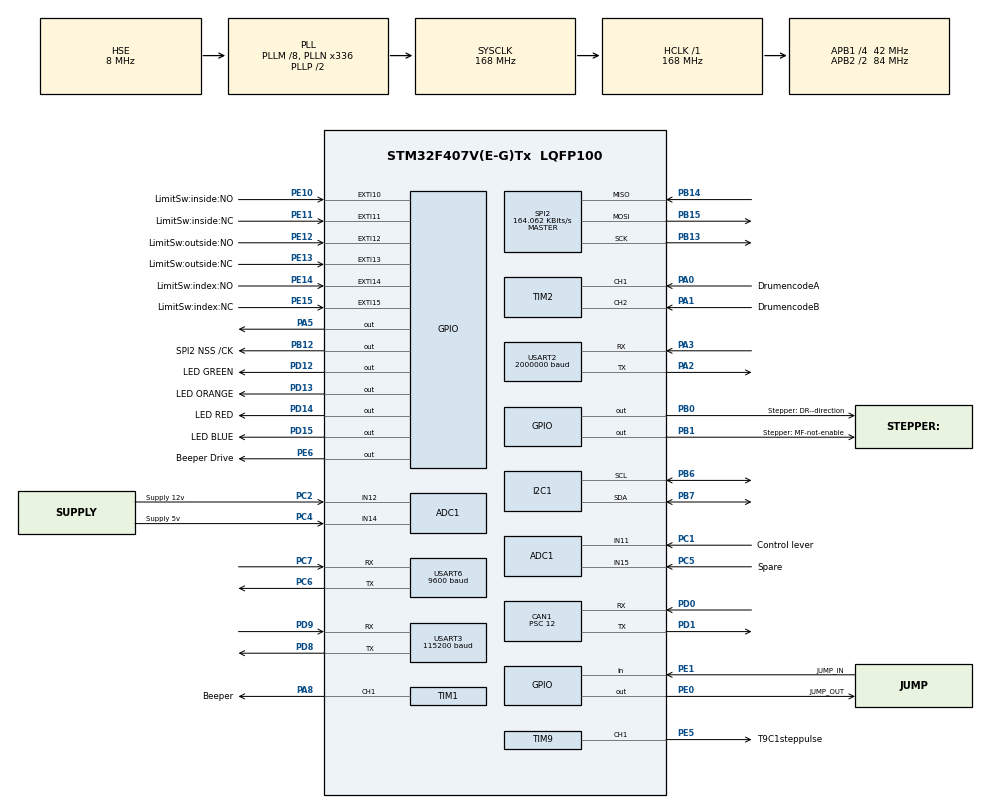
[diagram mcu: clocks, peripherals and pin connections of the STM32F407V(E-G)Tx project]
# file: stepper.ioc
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ADC1.Channel-0\#ChannelRegularConversion=ADC_CHANNEL_11
ADC1.Channel-1\#ChannelRegularConversion=ADC_CHANNEL_12
ADC1.Channel-10\#ChannelRegularConversion=ADC_CHANNEL_TEMPSENSOR
ADC1.Channel-11\#ChannelRegularConversion=ADC_CHANNEL_VREFINT
ADC1.Channel-2\#ChannelRegularConversion=ADC_CHANNEL_14
ADC1.Channel-3\#ChannelRegularConversion=ADC_CHANNEL_15
ADC1.ContinuousConvMode=ENABLE
ADC1.DMAContinuousRequests=ENABLE
ADC1.NbrOfConversion=6
ADC1.NbrOfConversionFlag=1
ADC1.Rank-0\#ChannelRegularConversion=1
ADC1.Rank-1\#ChannelRegularConversion=2
ADC1.Rank-10\#ChannelRegularConversion=5
ADC1.Rank-11\#ChannelRegularConversion=6
ADC1.Rank-2\#ChannelRegularConversion=3
ADC1.Rank-3\#ChannelRegularConversion=4
ADC1.SamplingTime-0\#ChannelRegularConversion=ADC_SAMPLETIME_84CYCLES
ADC1.SamplingTime-1\#ChannelRegularConversion=ADC_SAMPLETIME_84CYCLES
ADC1.SamplingTime-10\#ChannelRegularConversion=ADC_SAMPLETIME_480CYCLES
ADC1.SamplingTime-11\#ChannelRegularConversion=ADC_SAMPLETIME_480CYCLES
ADC1.SamplingTime-2\#ChannelRegularConversion=ADC_SAMPLETIME_84CYCLES
ADC1.SamplingTime-3\#ChannelRegularConversion=ADC_SAMPLETIME_84CYCLES
ADC1.ScanConvMode=ENABLE
ADC1.master=1
CAN1.BS1=CAN_BS1_5TQ
CAN1.CalculateTimeQuantum=285.7142857142857
CAN1.Prescaler=12
Dma.ADC1.4.Direction=DMA_PERIPH_TO_MEMORY
Dma.ADC1.4.FIFOMode=DMA_FIFOMODE_DISABLE
Dma.ADC1.4.Instance=DMA2_Stream0
Dma.ADC1.4.MemDataAlignment=DMA_MDATAALIGN_HALFWORD
Dma.ADC1.4.MemInc=DMA_MINC_ENABLE
Dma.ADC1.4.Mode=DMA_CIRCULAR
Dma.ADC1.4.PeriphDataAlignment=DMA_PDATAALIGN_HALFWORD
Dma.ADC1.4.PeriphInc=DMA_PINC_DISABLE
Dma.ADC1.4.Priority=DMA_PRIORITY_LOW
Dma.I2C1_RX.8.Direction=DMA_PERIPH_TO_MEMORY
Dma.I2C1_RX.8.FIFOMode=DMA_FIFOMODE_DISABLE
Dma.I2C1_RX.8.Instance=DMA1_Stream0
Dma.I2C1_RX.8.MemDataAlignment=DMA_MDATAALIGN_BYTE
Dma.I2C1_RX.8.MemInc=DMA_MINC_ENABLE
Dma.I2C1_RX.8.Mode=DMA_NORMAL
Dma.I2C1_RX.8.PeriphDataAlignment=DMA_PDATAALIGN_BYTE
Dma.I2C1_RX.8.PeriphInc=DMA_PINC_DISABLE
Dma.I2C1_RX.8.Priority=DMA_PRIORITY_LOW
Dma.I2C1_TX.7.Direction=DMA_MEMORY_TO_PERIPH
Dma.I2C1_TX.7.FIFOMode=DMA_FIFOMODE_DISABLE
Dma.I2C1_TX.7.Instance=DMA1_Stream7
Dma.I2C1_TX.7.MemDataAlignment=DMA_MDATAALIGN_BYTE
Dma.I2C1_TX.7.MemInc=DMA_MINC_ENABLE
Dma.I2C1_TX.7.Mode=DMA_NORMAL
Dma.I2C1_TX.7.PeriphDataAlignment=DMA_PDATAALIGN_BYTE
Dma.I2C1_TX.7.PeriphInc=DMA_PINC_DISABLE
Dma.I2C1_TX.7.Priority=DMA_PRIORITY_LOW
Dma.Request0=USART2_RX
Dma.Request1=USART2_TX
Dma.Request2=USART6_RX
Dma.Request3=USART6_TX
Dma.Request4=ADC1
Dma.Request5=USART3_RX
Dma.Request6=USART3_TX
Dma.Request7=I2C1_TX
Dma.Request8=I2C1_RX
Dma.USART2_RX.0.Direction=DMA_PERIPH_TO_MEMORY
Dma.USART2_RX.0.FIFOMode=DMA_FIFOMODE_DISABLE
Dma.USART2_RX.0.Instance=DMA1_Stream5
Dma.USART2_RX.0.MemDataAlignment=DMA_MDATAALIGN_BYTE
Dma.USART2_RX.0.MemInc=DMA_MINC_ENABLE
Dma.USART2_RX.0.Mode=DMA_CIRCULAR
Dma.USART2_RX.0.PeriphDataAlignment=DMA_PDATAALIGN_BYTE
Dma.USART2_RX.0.PeriphInc=DMA_PINC_DISABLE
Dma.USART2_RX.0.Priority=DMA_PRIORITY_LOW
Dma.USART2_TX.1.Direction=DMA_MEMORY_TO_PERIPH
Dma.USART2_TX.1.FIFOMode=DMA_FIFOMODE_DISABLE
Dma.USART2_TX.1.Instance=DMA1_Stream6
Dma.USART2_TX.1.MemDataAlignment=DMA_MDATAALIGN_BYTE
Dma.USART2_TX.1.MemInc=DMA_MINC_ENABLE
Dma.USART2_TX.1.Mode=DMA_NORMAL
Dma.USART2_TX.1.PeriphDataAlignment=DMA_PDATAALIGN_BYTE
Dma.USART2_TX.1.PeriphInc=DMA_PINC_DISABLE
Dma.USART2_TX.1.Priority=DMA_PRIORITY_LOW
Dma.USART3_RX.5.Direction=DMA_PERIPH_TO_MEMORY
Dma.USART3_RX.5.FIFOMode=DMA_FIFOMODE_DISABLE
Dma.USART3_RX.5.Instance=DMA1_Stream1
Dma.USART3_RX.5.MemDataAlignment=DMA_MDATAALIGN_BYTE
Dma.USART3_RX.5.MemInc=DMA_MINC_ENABLE
Dma.USART3_RX.5.Mode=DMA_NORMAL
Dma.USART3_RX.5.PeriphDataAlignment=DMA_PDATAALIGN_BYTE
Dma.USART3_RX.5.PeriphInc=DMA_PINC_DISABLE
Dma.USART3_RX.5.Priority=DMA_PRIORITY_LOW
Dma.USART3_TX.6.Direction=DMA_MEMORY_TO_PERIPH
Dma.USART3_TX.6.FIFOMode=DMA_FIFOMODE_DISABLE
Dma.USART3_TX.6.Instance=DMA1_Stream3
Dma.USART3_TX.6.MemDataAlignment=DMA_MDATAALIGN_BYTE
Dma.USART3_TX.6.MemInc=DMA_MINC_ENABLE
Dma.USART3_TX.6.Mode=DMA_NORMAL
Dma.USART3_TX.6.PeriphDataAlignment=DMA_PDATAALIGN_BYTE
Dma.USART3_TX.6.PeriphInc=DMA_PINC_DISABLE
Dma.USART3_TX.6.Priority=DMA_PRIORITY_LOW
Dma.USART6_RX.2.Direction=DMA_PERIPH_TO_MEMORY
Dma.USART6_RX.2.FIFOMode=DMA_FIFOMODE_DISABLE
Dma.USART6_RX.2.Instance=DMA2_Stream1
Dma.USART6_RX.2.MemDataAlignment=DMA_MDATAALIGN_BYTE
Dma.USART6_RX.2.MemInc=DMA_MINC_ENABLE
Dma.USART6_RX.2.Mode=DMA_CIRCULAR
Dma.USART6_RX.2.PeriphDataAlignment=DMA_PDATAALIGN_BYTE
Dma.USART6_RX.2.PeriphInc=DMA_PINC_DISABLE
Dma.USART6_RX.2.Priority=DMA_PRIORITY_LOW
Dma.USART6_TX.3.Direction=DMA_MEMORY_TO_PERIPH
Dma.USART6_TX.3.FIFOMode=DMA_FIFOMODE_DISABLE
Dma.USART6_TX.3.Instance=DMA2_Stream6
Dma.USART6_TX.3.MemDataAlignment=DMA_MDATAALIGN_BYTE
Dma.USART6_TX.3.MemInc=DMA_MINC_ENABLE
Dma.USART6_TX.3.Mode=DMA_NORMAL
Dma.USART6_TX.3.PeriphDataAlignment=DMA_PDATAALIGN_BYTE
Dma.USART6_TX.3.PeriphInc=DMA_PINC_DISABLE
Dma.USART6_TX.3.Priority=DMA_PRIORITY_LOW
FREERTOS.INCLUDE_uxTaskGetStackHighWaterMark=1
FREERTOS.INCLUDE_vTaskDelayUntil=1
FREERTOS.INCLUDE_vTaskDelete=0
FREERTOS.INCLUDE_xTaskGetCurrentTaskHandle=1
FREERTOS.MEMORY_ALLOCATION=2
FREERTOS.Tasks01=defaultTask,0,384,StartDefaultTask,Default,NULL,Dynamic,NULL,NULL
FREERTOS.Timers01=defaultTaskTimer,CallbackdefaultTaskTimer,osTimerPeriodic,Default,NULL,Dynamic,NULL
FREERTOS.configCHECK_FOR_STACK_OVERFLOW=2
FREERTOS.configMINIMAL_STACK_SIZE=96
FREERTOS.configQUEUE_REGISTRY_SIZE=12
FREERTOS.configTICK_RATE_HZ=512
FREERTOS.configTOTAL_HEAP_SIZE=32768
FREERTOS.configUSE_TIMERS=1
Mcu.Family=STM32F4
Mcu.Name=STM32F407V(E-G)Tx
Mcu.Package=LQFP100
NVIC.ADC_IRQn=true\:6\:0\:true\:false\:true\:true\:true\:true
NVIC.CAN1_RX0_IRQn=true\:7\:0\:true\:false\:true\:true\:true\:true
NVIC.CAN1_RX1_IRQn=true\:7\:0\:true\:false\:true\:true\:true\:true
NVIC.CAN1_TX_IRQn=true\:7\:0\:true\:false\:true\:true\:true\:true
NVIC.DMA1_Stream0_IRQn=true\:8\:0\:true\:false\:true\:true\:false\:true
NVIC.DMA1_Stream1_IRQn=true\:10\:0\:true\:false\:true\:true\:false\:true
NVIC.DMA1_Stream3_IRQn=true\:10\:0\:true\:false\:true\:true\:false\:true
NVIC.DMA1_Stream5_IRQn=true\:6\:0\:true\:false\:true\:true\:false\:true
NVIC.DMA1_Stream6_IRQn=true\:6\:0\:true\:false\:true\:true\:false\:true
NVIC.DMA1_Stream7_IRQn=true\:12\:0\:true\:false\:true\:true\:false\:true
NVIC.DMA2_Stream0_IRQn=true\:6\:0\:true\:false\:true\:true\:false\:true
NVIC.DMA2_Stream1_IRQn=true\:11\:0\:true\:false\:true\:true\:false\:true
NVIC.DMA2_Stream6_IRQn=true\:11\:0\:true\:false\:true\:true\:false\:true
NVIC.EXTI15_10_IRQn=true\:11\:0\:true\:false\:true\:true\:true\:true
NVIC.I2C1_EV_IRQn=true\:10\:0\:true\:false\:true\:true\:true\:true
NVIC.PriorityGroup=NVIC_PRIORITYGROUP_4
NVIC.SPI2_IRQn=true\:13\:0\:true\:false\:true\:true\:true\:true
NVIC.TIM1_BRK_TIM9_IRQn=true\:4\:0\:true\:false\:true\:false\:true\:true
NVIC.TIM3_IRQn=true\:2\:0\:true\:false\:true\:false\:true\:true
NVIC.TIM8_BRK_TIM12_IRQn=true\:0\:0\:false\:false\:true\:false\:false\:true
NVIC.TimeBase=TIM8_BRK_TIM12_IRQn
NVIC.TimeBaseIP=TIM12
NVIC.USART2_IRQn=true\:6\:0\:true\:false\:true\:true\:true\:true
NVIC.USART3_IRQn=true\:8\:0\:true\:false\:true\:true\:true\:true
NVIC.USART6_IRQn=true\:9\:0\:true\:false\:true\:true\:true\:true
PA0-WKUP.GPIO_Label=DrumencodeA
PA0-WKUP.GPIO_PuPd=GPIO_PULLUP
PA0-WKUP.GPIO_Speed=GPIO_SPEED_FREQ_MEDIUM
PA0-WKUP.Signal=S_TIM2_CH1_ETR
PA1.GPIO_Label=DrumencodeB
PA1.GPIO_PuPd=GPIO_PULLUP
PA1.GPIO_Speed=GPIO_SPEED_FREQ_MEDIUM
PA1.Signal=S_TIM2_CH2
PA13.Mode=Serial_Wire
PA13.Signal=SYS_JTMS-SWDIO
PA14.Mode=Serial_Wire
PA14.Signal=SYS_JTCK-SWCLK
PA2.Mode=Asynchronous
PA2.Signal=USART2_TX
PA3.Mode=Asynchronous
PA3.Signal=USART2_RX
PA5.Signal=GPIO_Output
PA8.GPIO_Label=Beeper
PA8.Signal=S_TIM1_CH1
PB0.GPIO_Label=Stepper\: DR--direction
PB0.GPIO_Speed=GPIO_SPEED_FREQ_MEDIUM
PB0.Signal=GPIO_Output
PB1.GPIO_Label=Stepper\: MF-not-enable
PB1.Signal=GPIO_Output
PB12.GPIO_Label=SPI2 NSS /CK
PB12.GPIO_PuPd=GPIO_PULLUP
PB12.GPIO_Speed=GPIO_SPEED_FREQ_MEDIUM
PB12.Signal=GPIO_Output
PB13.Mode=Full_Duplex_Master
PB13.Signal=SPI2_SCK
PB14.Mode=Full_Duplex_Master
PB14.Signal=SPI2_MISO
PB15.Mode=Full_Duplex_Master
PB15.Signal=SPI2_MOSI
PB6.Mode=I2C
PB6.Signal=I2C1_SCL
PB7.Mode=I2C
PB7.Signal=I2C1_SDA
PC1.GPIO_Label=Control lever
PC1.Signal=ADCx_IN11
PC2.GPIO_Label=Supply 12v
PC2.Signal=ADCx_IN12
PC4.GPIO_Label=Supply 5v
PC4.Signal=ADCx_IN14
PC5.GPIO_Label=Spare
PC5.Signal=ADCx_IN15
PC6.Mode=Asynchronous
PC6.Signal=USART6_TX
PC7.Mode=Asynchronous
PC7.Signal=USART6_RX
PD0.Mode=Master
PD0.Signal=CAN1_RX
PD1.Mode=Master
PD1.Signal=CAN1_TX
PD12.GPIO_Label=LED GREEN
PD12.Signal=GPIO_Output
PD13.GPIO_Label=LED ORANGE
PD13.Signal=GPIO_Output
PD14.GPIO_Label=LED RED
PD14.Signal=GPIO_Output
PD15.GPIO_Label=LED BLUE
PD15.Signal=GPIO_Output
PD8.Mode=Asynchronous
PD8.Signal=USART3_TX
PD9.Mode=Asynchronous
PD9.Signal=USART3_RX
PE0.GPIO_Label=JUMP_OUT
PE0.GPIO_Speed=GPIO_SPEED_FREQ_MEDIUM
PE0.Signal=GPIO_Output
PE1.GPIO_Label=JUMP_IN
PE1.GPIO_PuPd=GPIO_PULLDOWN
PE1.Signal=GPIO_Input
PE10.GPIO_Label=LimitSw\:inside\:NO
PE10.GPIO_PuPd=GPIO_PULLUP
PE10.Signal=GPXTI10
PE11.GPIO_Label=LimitSw\:inside\:NC
PE11.GPIO_PuPd=GPIO_PULLUP
PE11.Signal=GPXTI11
PE12.GPIO_Label=LimitSw\:outside\:NO
PE12.GPIO_PuPd=GPIO_PULLUP
PE12.Signal=GPXTI12
PE13.GPIO_Label=LimitSw\:outside\:NC
PE13.GPIO_PuPd=GPIO_PULLUP
PE13.Signal=GPXTI13
PE14.GPIO_Label=LimitSw\:index\:NO
PE14.GPIO_PuPd=GPIO_PULLUP
PE14.Signal=GPXTI14
PE15.GPIO_Label=LimitSw\:index\:NC
PE15.GPIO_PuPd=GPIO_PULLUP
PE15.Signal=GPXTI15
PE5.GPIO_Label=T9C1steppulse
PE5.GPIO_PuPd=GPIO_PULLUP
PE5.GPIO_Speed=GPIO_SPEED_FREQ_VERY_HIGH
PE5.Signal=S_TIM9_CH1
PE6.GPIO_Label=Beeper Drive
PE6.GPIO_ModeDefaultOutputPP=GPIO_MODE_OUTPUT_PP
PE6.GPIO_PuPd=GPIO_NOPULL
PE6.GPIO_Speed=GPIO_SPEED_FREQ_LOW
PE6.PinState=GPIO_PIN_RESET
PE6.Signal=GPIO_Output
PH0-OSC_IN.Mode=HSE-External-Oscillator
PH0-OSC_IN.Signal=RCC_OSC_IN
PH1-OSC_OUT.Mode=HSE-External-Oscillator
PH1-OSC_OUT.Signal=RCC_OSC_OUT
ProjectManager.HeapSize=0x200
ProjectManager.StackSize=0x400
ProjectManager.TargetToolchain=Makefile
RCC.48MHZClocksFreq_Value=48000000
RCC.AHBFreq_Value=168000000
RCC.APB1CLKDivider=RCC_HCLK_DIV4
RCC.APB1Freq_Value=42000000
RCC.APB1TimFreq_Value=84000000
RCC.APB2CLKDivider=RCC_HCLK_DIV2
RCC.APB2Freq_Value=84000000
RCC.APB2TimFreq_Value=168000000
RCC.CortexFreq_Value=168000000
RCC.HCLKFreq_Value=168000000
RCC.HSE_VALUE=8000000
RCC.HSI_VALUE=16000000
RCC.LSE_VALUE=32768
RCC.PLLM=8
RCC.PLLN=336
RCC.PLLQ=7
RCC.PLLSourceVirtual=RCC_PLLSOURCE_HSE
RCC.SYSCLKFreq_VALUE=168000000
RCC.SYSCLKSource=RCC_SYSCLKSOURCE_PLLCLK
RCC.VCOOutputFreq_Value=336000000
SH.ADCx_IN11.0=ADC1_IN11,IN11
SH.ADCx_IN12.0=ADC1_IN12,IN12
SH.ADCx_IN14.0=ADC1_IN14,IN14
SH.ADCx_IN15.0=ADC1_IN15,IN15
SH.S_TIM1_CH1.0=TIM1_CH1,PWM Generation1 CH1
SH.S_TIM2_CH1_ETR.0=TIM2_CH1,Encoder_Interface
SH.S_TIM2_CH2.0=TIM2_CH2,Encoder_Interface
SH.S_TIM9_CH1.0=TIM9_CH1,PWM Generation1 CH1
SPI2.BaudRatePrescaler=SPI_BAUDRATEPRESCALER_256
SPI2.CLKPhase=SPI_PHASE_1EDGE
SPI2.CLKPolarity=SPI_POLARITY_LOW
SPI2.CalculateBaudRate=164.062 KBits/s
SPI2.Direction=SPI_DIRECTION_2LINES
SPI2.Mode=SPI_MODE_MASTER
SPI2.VirtualType=VM_MASTER
TIM1.AutoReloadPreload=TIM_AUTORELOAD_PRELOAD_DISABLE
TIM1.Channel-PWM\ Generation1\ CH1=TIM_CHANNEL_1
TIM1.Period=35000
TIM1.Pulse-PWM\ Generation1\ CH1=15700
TIM1.TIM_MasterOutputTrigger=TIM_TRGO_OC1REF
TIM3.Channel-Output\ Compare1\ No\ Output=TIM_CHANNEL_1
TIM3.Period=1680
TIM5.Channel-Output\ Compare1\ No\ Output=TIM_CHANNEL_1
TIM9.Channel-PWM\ Generation1\ CH1=TIM_CHANNEL_1
TIM9.OCPolarity_1=TIM_OCPOLARITY_HIGH
TIM9.Period=1680
TIM9.Pulse-PWM\ Generation1\ CH1=504
USART2.BaudRate=2000000
USART2.VirtualMode=VM_ASYNC
USART3.BaudRate=115200
USART3.VirtualMode=VM_ASYNC
USART6.BaudRate=9600
USART6.VirtualMode=VM_ASYNC
VP_ADC1_TempSens_Input.Mode=IN-TempSens
VP_ADC1_Vref_Input.Mode=IN-Vrefint
VP_FREERTOS_VS_CMSIS_V1.Mode=CMSIS_V1
VP_SYS_VS_tim12.Mode=TIM12
VP_TIM1_VS_ClockSourceINT.Mode=Internal
VP_TIM3_VS_ClockSourceINT.Mode=Internal
VP_TIM3_VS_no_output1.Mode=Output Compare1 No Output
VP_TIM5_VS_ClockSourceINT.Mode=Internal
VP_TIM5_VS_no_output1.Mode=Output Compare1 No Output
VP_TIM9_VS_ClockSourceINT.Mode=Internal
VP_TIM9_VS_OPM.Mode=OPM_bit
board=custom

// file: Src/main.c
/* USER CODE BEGIN Header */
/**
  ******************************************************************************
  * @file           : main.c
  * @brief          : Main program body
  ******************************************************************************
  * This notice applies to any and all portions of this file
  * that are not between comment pairs USER CODE BEGIN and
  * USER CODE END. Other portions of this file, whether
  * inserted by the user or by software development tools
  * are owned by their respective copyright owners.
  *
  * Copyright (c) 2019 STMicroelectronics International N.V.
  * All rights reserved.
  *
  * Redistribution and use in source and binary forms, with or without
  * modification, are permitted, provided that the following conditions are met:
  *
  * 1. Redistribution of source code must retain the above copyright notice,
  *    this list of conditions and the following disclaimer.
  * 2. Redistributions in binary form must reproduce the above copyright notice,
  *    this list of conditions and the following disclaimer in the documentation
  *    and/or other materials provided with the distribution.
  * 3. Neither the name of STMicroelectronics nor the names of other
  *    contributors to this software may be used to endorse or promote products
  *    derived from this software without specific written permission.
  * 4. This software, including modifications and/or derivative works of this
  *    software, must execute solely and exclusively on microcontroller or
  *    microprocessor devices manufactured by or for STMicroelectronics.
  * 5. Redistribution and use of this software other than as permitted under
  *    this license is void and will automatically terminate your rights under
  *    this license.
  *
  * THIS SOFTWARE IS PROVIDED BY STMICROELECTRONICS AND CONTRIBUTORS "AS IS"
  * AND ANY EXPRESS, IMPLIED OR STATUTORY WARRANTIES, INCLUDING, BUT NOT
  * LIMITED TO, THE IMPLIED WARRANTIES OF MERCHANTABILITY, FITNESS FOR A
  * PARTICULAR PURPOSE AND NON-INFRINGEMENT OF THIRD PARTY INTELLECTUAL PROPERTY
  * RIGHTS ARE DISCLAIMED TO THE FULLEST EXTENT PERMITTED BY LAW. IN NO EVENT
  * SHALL STMICROELECTRONICS OR CONTRIBUTORS BE LIABLE FOR ANY DIRECT, INDIRECT,
  * INCIDENTAL, SPECIAL, EXEMPLARY, OR CONSEQUENTIAL DAMAGES (INCLUDING, BUT NOT
  * LIMITED TO, PROCUREMENT OF SUBSTITUTE GOODS OR SERVICES; LOSS OF USE, DATA,
  * OR PROFITS; OR BUSINESS INTERRUPTION) HOWEVER CAUSED AND ON ANY THEORY OF
  * LIABILITY, WHETHER IN CONTRACT, STRICT LIABILITY, OR TORT (INCLUDING
  * NEGLIGENCE OR OTHERWISE) ARISING IN ANY WAY OUT OF THE USE OF THIS SOFTWARE,
  * EVEN IF ADVISED OF THE POSSIBILITY OF SUCH DAMAGE.
  *
  ******************************************************************************
  */
/* USER CODE END Header */
#include "main.h"
#include "cmsis_os.h"

/* USER CODE BEGIN Includes */
#include <string.h>
#include "SerialTaskSend.h"
#include "stm32f4xx_hal_pcd.h"
//#include "usbd_cdc_if.h"
#include "cdc_txbuff.h"
#include "CanTask.h"
#include "can_iface.h"
#include "canfilter_setup.h"
#include "stm32f4xx_hal_can.h"
#include "getserialbuf.h"
#include "stackwatermark.h"
#include "yprintf.h"
#include "gateway_comm.h"
#include "gateway_CANtoPC.h"
#include "DTW_counter.h"
#include "SerialTaskReceive.h"
#include "yscanf.h"
#include "adctask.h"
#include "ADCTask.h"
#include "adcparams.h"
#include "adcparamsinit.h"
#include "gateway_PCtoCAN.h"
#include "morse.h"
#include "MailboxTask.h"
#include "GatewayTask.h"
#include "iir_f2.h"
#include "spiserialparallelSW.h"
#include "cdc_txbuff.h"
#include "SpiOutTask.h"
#include "BeepTask.h"
#include "lcdprintf.h"
#include "LEDTask.h"
#include "led_chasing.h"
#include "calib_control_lever.h"
#include "lcdmsg.h"
#include "dmoc_control.h"
#include "control_law_v1.h"

#include "LcdTask.h"
#include "lcd_hd44780_i2c.h"
#include "LcdmsgsTask.h"
#include "LcdmsgsetTask.h"
#include "stepper_items.h"

/* USER CODE END Includes */

/* USER CODE BEGIN PTD */

void* verr[8];
uint32_t verrx = 0;
__attribute__( ( always_inline ) ) __STATIC_INLINE uint32_t __get_SP(void)
{
  register uint32_t result;

  __ASM volatile ("MOV %0, SP\n" : "=r" (result) );
  return(result);
}

uint32_t timectr = 0;
struct CAN_CTLBLOCK* pctl0;	// Pointer to CAN1 control block
struct CAN_CTLBLOCK* pctl1;	// Pointer to CAN2 control block

uint32_t debugTX1b;
uint32_t debugTX1b_prev;

uint32_t debugTX1c;
uint32_t debugTX1c_prev;

uint32_t debug03;
uint32_t debug03_prev;

extern osThreadId SerialTaskHandle;
extern osThreadId CanTxTaskHandle;
extern osThreadId CanRxTaskHandle;
extern osThreadId SerialTaskReceiveHandle;
extern osThreadId GatewayTaskHandle;

uint16_t m_trap = 450; // Trap codes for MX Init() and Error Handler

uint8_t canflag;
uint8_t canflag1;
uint8_t canflag2;

uint8_t lcdflag = 0;

// PE0-PE1 jumper test
uint32_t PE01test; // 0 = GSM; not 0 = DEH

/* USER CODE END PTD */

ADC_HandleTypeDef hadc1;
DMA_HandleTypeDef hdma_adc1;

CAN_HandleTypeDef hcan1;

I2C_HandleTypeDef hi2c1;
DMA_HandleTypeDef hdma_i2c1_tx;
DMA_HandleTypeDef hdma_i2c1_rx;

SPI_HandleTypeDef hspi2;

TIM_HandleTypeDef htim1;
TIM_HandleTypeDef htim2;
TIM_HandleTypeDef htim3;
TIM_HandleTypeDef htim5;
TIM_HandleTypeDef htim9;

UART_HandleTypeDef huart2;
UART_HandleTypeDef huart3;
UART_HandleTypeDef huart6;
DMA_HandleTypeDef hdma_usart2_rx;
DMA_HandleTypeDef hdma_usart2_tx;
DMA_HandleTypeDef hdma_usart3_rx;
DMA_HandleTypeDef hdma_usart3_tx;
DMA_HandleTypeDef hdma_usart6_rx;
DMA_HandleTypeDef hdma_usart6_tx;

osThreadId defaultTaskHandle;
osTimerId defaultTaskTimerHandle;

void SystemClock_Config(void);
static void MX_GPIO_Init(void);
static void MX_DMA_Init(void);
static void MX_USART6_UART_Init(void);
static void MX_USART2_UART_Init(void);
static void MX_CAN1_Init(void);
static void MX_ADC1_Init(void);
static void MX_SPI2_Init(void);
static void MX_USART3_UART_Init(void);
static void MX_TIM1_Init(void);
static void MX_I2C1_Init(void);
static void MX_TIM2_Init(void);
static void MX_TIM3_Init(void);
static void MX_TIM5_Init(void);
static void MX_TIM9_Init(void);
void StartDefaultTask(void const * argument);
void CallbackdefaultTaskTimer(void const * argument);

int main(void)
{
  /* USER CODE BEGIN 1 */
	BaseType_t ret;	   // Used for returns from function calls
	osMessageQId Qidret; // Function call return
	osThreadId Thrdret;  // Return from thread create

// Debug: Clear heap area
//uint32_t* pclr = (uint32_t*)(0x2000bb80);
//while (pclr < (uint32_t*)(0x2000bb80 + 32768)) *pclr++ = 0x66666666;

  /* USER CODE END 1 */

  /* MCU Configuration--------------------------------------------------------*/

  /* Reset of all peripherals, Initializes the Flash interface and the Systick. */
  HAL_Init();

  /* USER CODE BEGIN Init */
	DTW_counter_init();
  /* USER CODE END Init */

  /* Configure the system clock */
  SystemClock_Config();

  /* USER CODE BEGIN SysInit */
	/* Add bcb circular buffer to SerialTaskSend for uart6 -- LCD */
	#define NUMCIRBCB6  16 // Size of circular buffer of BCB for uart6
	ret = xSerialTaskSendAdd(&HUARTLCD, NUMCIRBCB6, 1); // dma
	if (ret < 0) morse_trap(1); // Panic LED flashing

	/* Add bcb circular buffer to SerialTaskSend for usart2 -- gateway */
	#define NUMCIRBCB2  16 // Size of circular buffer of BCB for usart2
	ret = xSerialTaskSendAdd(&huart2, NUMCIRBCB2, 1); // dma
	if (ret < 0) morse_trap(2); // Panic LED flashing

	/* Add bcb circular buffer to SerialTaskSend for usart3 -- PC monitor */
	#define NUMCIRBCB3  16 // Size of circular buffer of BCB for usart3
	ret = xSerialTaskSendAdd(&HUARTMON, NUMCIRBCB3, 1); // dma
	if (ret < 0) morse_trap(14); // Panic LED flashing

	/* Setup TX linked list for CAN  */
   // CAN1 (CAN_HandleTypeDef *phcan, uint8_t canidx, uint16_t numtx, uint16_t numrx);
	pctl0 = can_iface_init(&hcan1, 0, 32, 32);
	if (pctl0 == NULL) morse_trap(7); // Panic LED flashing
	if (pctl0->ret < 0) morse_trap(77);

	// CAN 2
#ifdef CONFIGCAN2
	pctl1 = can_iface_init(&hcan2, 1,32, 64);
	if (pctl1 == NULL) morse_trap(8); // Panic LED flashing
	if (pctl1->ret < 0) morse_trap(88);
#endif

  /* USER CODE END SysInit */

  /* Initialize all configured peripherals */
  MX_GPIO_Init();
  MX_DMA_Init();
  MX_USART6_UART_Init();
  MX_USART2_UART_Init();
  MX_CAN1_Init();
  MX_ADC1_Init();
  MX_SPI2_Init();
  MX_USART3_UART_Init();
  MX_TIM1_Init();
  MX_I2C1_Init();
  MX_TIM2_Init();
  MX_TIM3_Init();
  MX_TIM5_Init();
  MX_TIM9_Init();
  /* USER CODE BEGIN 2 */

/*
DiscoveryF4 LEDs --
 GPIOD, GPIO_PIN_12 GREEN
 GPIOD, GPIO_PIN_13 ORANGE
 GPIOD, GPIO_PIN_14 RED
 GPIOD, GPIO_PIN_15 BLUE
*/
  /* USER CODE END 2 */

  /* Create the timer(s) */
  /* definition and creation of defaultTaskTimer */
  osTimerDef(defaultTaskTimer, CallbackdefaultTaskTimer);
  defaultTaskTimerHandle = osTimerCreate(osTimer(defaultTaskTimer), osTimerPeriodic, NULL);

  /* USER CODE BEGIN RTOS_TIMERS */
  /* start timers, add new ones, ... */

	/* defaultTask timer for pacing defaultTask output. */
//	ret = xTimerChangePeriod( defaultTaskTimerHandle  ,pdMS_TO_TICKS(64),0);

  /* USER CODE END RTOS_TIMERS */

  /* Create the thread(s) */
  /* definition and creation of defaultTask */
  osThreadDef(defaultTask, StartDefaultTask, osPriorityNormal, 0, 384);
  defaultTaskHandle = osThreadCreate(osThread(defaultTask), NULL);

  /* USER CODE BEGIN RTOS_THREADS */
  /* add threads, ... */
/* =================================================== */
  /* init code for USB_DEVICE */

//taskENTER_CRITICAL();
  //MX_USB_DEVICE_Init();
  //osDelay(0);
//taskEXIT_CRITICAL();

  /* Test for jumper of DiscoveryF4 board PE0-PE1. */
  // PE1 high == DEH setup
  //HAL_GPIO_WritePin(JUMP_OUT_GPIO_Port,JUMP_OUT_Pin,GPIO_PIN_SET);
  //PE01test = HAL_GPIO_ReadPin(JUMP_IN_GPIO_Port,JUMP_IN_Pin);
  //if (PE01test == 0)
 // {
//    htim2.Instance->CCR1 = 35001;
//  }

	/* Create serial task (priority) */
	// Task handle "osThreadId SerialTaskHandle" is global
	Thrdret = xSerialTaskSendCreate(1);	// Create task and set Task priority
	if (Thrdret == NULL) morse_trap(225);

	/* Create serial receiving task. */
	ret = xSerialTaskReceiveCreate(1);
	if (ret != pdPASS) morse_trap(224);

	/* Setup semaphore for yprint and sprintf et al. */
	yprintf_init();

  /* definition and creation of CanTxTask - CAN driver TX interface. */
  Qidret = xCanTxTaskCreate(2, 64); // CanTask priority, Number of msgs in queue
	if (Qidret < 0) morse_trap(220); // Panic LED flashing

  /* definition and creation of CanRxTask - CAN driver RX interface. */
  /* The MailboxTask takes care of the CANRx                         */
  Qidret = xCanRxTaskCreate(1, 32); // CanTask priority, Number of msgs in queue
	if (Qidret < 0) morse_trap(6); // Panic LED flashing

	/* Setup CAN hardware filters to default to accept all ids. */
	HAL_StatusTypeDef Cret;
	Cret = canfilter_setup_first(0, &hcan1, 15); // CAN1
	if (Cret == HAL_ERROR) morse_trap(219);

#ifdef CONFIGCAN2
	Cret = canfilter_setup_first(1, &hcan2, 15); // CAN2
	if (Cret == HAL_ERROR) morse_trap(217);
#endif

	/* Remove "accept all" CAN msgs and add specific id & mask, or id here. */
	// See canfilter_setup.h

	/* Create MailboxTask */
	xMailboxTaskCreate(2); // (arg) = priority

	/* Create GatewayTask */
	xGatewayTaskCreate(2); // (arg) = priority

	/* GEVCUr state machine. */
	Thrdret = xGevcuTaskCreate(2); // (arg) = priority
	if (Thrdret == NULL) morse_trap(216);

	/* Create Mailbox control block w 'take' pointer for each CAN module. */
	struct MAILBOXCANNUM* pmbxret;
	// (CAN1 control block pointer, size of circular buffer)
	pmbxret = MailboxTask_add_CANlist(pctl0, 48);
	if (pmbxret == NULL) morse_trap(215);

#ifdef CONFIGCAN2
	// (CAN2 control block pointer, size of circular buffer)
	pmbxret = MailboxTask_add_CANlist(pctl1, 48); // Use default buff size
	if (pmbxret == NULL) morse_trap(214);
#endif

	/* Further initialization of mailboxes takes place when tasks start */

	/* Select interrupts for CAN1 */
	HAL_CAN_ActivateNotification(&hcan1, \
		CAN_IT_TX_MAILBOX_EMPTY     |  \
		CAN_IT_RX_FIFO0_MSG_PENDING |  \
		CAN_IT_RX_FIFO1_MSG_PENDING    );

	/* Select interrupts for CAN2 */
#ifdef CONFIGCAN2
	HAL_CAN_ActivateNotification(&hcan2, \
		CAN_IT_TX_MAILBOX_EMPTY     |  \
		CAN_IT_RX_FIFO0_MSG_PENDING |  \
		CAN_IT_RX_FIFO1_MSG_PENDING    );
#endif

	/* Switch logic from queue loaded by Spi interrupts. */
//	Thrdret = xSwitchTaskCreate(1);
//	if (Thrdret == NULL) morse_trap(20); // Panic LED flashing

	/* Spi shift register task. */
	Thrdret = xSpiOutTaskCreate(1);
	if (Thrdret == NULL) morse_trap(213); // Panic LED flashing

	/* Beeper task (taskpriority, beepqsize) */
	Thrdret = xBeepTaskCreate(0, 32);
	if (Thrdret == NULL) morse_trap(212); // Panic LED flashing

	/* LED task (taskpriority, max queued items) .*/
	Thrdret = xLEDTaskCreate(0, 32);
	if (Thrdret == NULL) morse_trap(211); // Panic LED flashing

	/* ADC summing, calibration, etc. */
	xADCTaskCreate(3); // (arg) = priority

	/* Start SPI for switch/led shift register. */
	if (spiserialparallel_init(&hspi2) != HAL_OK) morse_trap(49);

	/* Queue for running LCD out of defaultTask. */
	Qidret = lcdmsg_init(16);
	if (Qidret < 0) morse_trap(210); // Panic LED flashing

  /* LCD I2C: message handling. (taskpriority, number buffers). */
  osThreadId retThrd =  xLcdTaskCreate(0,16);
  if (retThrd == NULL) morse_trap(123);

  /* LCD I2C: message generation (calls to 'printf or'puts).
  'printf and overrun stalls take place in this task.
  (task priority, number in queue of pointer|union) */
  retThrd= xLcdmsgsetTaskCreate(0, 16);
  if (retThrd == NULL) morse_trap(125);

  /* init code for USB_DEVICE */
//taskENTER_CRITICAL();
  //MX_USB_DEVICE_Init();
//taskEXIT_CRITICAL();

/* =================================================== */

  /* USER CODE END RTOS_THREADS */

  /* Start scheduler */
  osKernelStart();

  /* We should never get here as control is now taken by the scheduler */
  /* Infinite loop */
  while (1)
  {

  }
}

void SystemClock_Config(void)
{
  RCC_OscInitTypeDef RCC_OscInitStruct = {0};
  RCC_ClkInitTypeDef RCC_ClkInitStruct = {0};

  /** Configure the main internal regulator output voltage
  */
  __HAL_RCC_PWR_CLK_ENABLE();
  __HAL_PWR_VOLTAGESCALING_CONFIG(PWR_REGULATOR_VOLTAGE_SCALE1);
  /** Initializes the RCC Oscillators according to the specified parameters
  * in the RCC_OscInitTypeDef structure.
  */
  RCC_OscInitStruct.OscillatorType = RCC_OSCILLATORTYPE_HSE;
  RCC_OscInitStruct.HSEState = RCC_HSE_ON;
  RCC_OscInitStruct.PLL.PLLState = RCC_PLL_ON;
  RCC_OscInitStruct.PLL.PLLSource = RCC_PLLSOURCE_HSE;
  RCC_OscInitStruct.PLL.PLLM = 8;
  RCC_OscInitStruct.PLL.PLLN = 336;
  RCC_OscInitStruct.PLL.PLLP = RCC_PLLP_DIV2;
  RCC_OscInitStruct.PLL.PLLQ = 7;
  if (HAL_RCC_OscConfig(&RCC_OscInitStruct) != HAL_OK)
  {
    Error_Handler();
  }
  /** Initializes the CPU, AHB and APB buses clocks
  */
  RCC_ClkInitStruct.ClockType = RCC_CLOCKTYPE_HCLK|RCC_CLOCKTYPE_SYSCLK
                              |RCC_CLOCKTYPE_PCLK1|RCC_CLOCKTYPE_PCLK2;
  RCC_ClkInitStruct.SYSCLKSource = RCC_SYSCLKSOURCE_PLLCLK;
  RCC_ClkInitStruct.AHBCLKDivider = RCC_SYSCLK_DIV1;
  RCC_ClkInitStruct.APB1CLKDivider = RCC_HCLK_DIV4;
  RCC_ClkInitStruct.APB2CLKDivider = RCC_HCLK_DIV2;

  if (HAL_RCC_ClockConfig(&RCC_ClkInitStruct, FLASH_LATENCY_5) != HAL_OK)
  {
    Error_Handler();
  }
}

static void MX_ADC1_Init(void)
{

  /* USER CODE BEGIN ADC1_Init 0 */
	m_trap = 457; // morse_trap(457);
  /* USER CODE END ADC1_Init 0 */

  ADC_ChannelConfTypeDef sConfig = {0};

  /** Configure the global features of the ADC (Clock, Resolution, Data Alignment and number of conversion)
  */
  hadc1.Instance = ADC1;
  hadc1.Init.ClockPrescaler = ADC_CLOCK_SYNC_PCLK_DIV4;
  hadc1.Init.Resolution = ADC_RESOLUTION_12B;
  hadc1.Init.ScanConvMode = ENABLE;
  hadc1.Init.ContinuousConvMode = ENABLE;
  hadc1.Init.DiscontinuousConvMode = DISABLE;
  hadc1.Init.ExternalTrigConvEdge = ADC_EXTERNALTRIGCONVEDGE_NONE;
  hadc1.Init.ExternalTrigConv = ADC_SOFTWARE_START;
  hadc1.Init.DataAlign = ADC_DATAALIGN_RIGHT;
  hadc1.Init.NbrOfConversion = 6;
  hadc1.Init.DMAContinuousRequests = ENABLE;
  hadc1.Init.EOCSelection = ADC_EOC_SINGLE_CONV;
  if (HAL_ADC_Init(&hadc1) != HAL_OK)
  {
    Error_Handler();
  }
  /** Configure for the selected ADC regular channel its corresponding rank in the sequencer and its sample time.
  */
  sConfig.Channel = ADC_CHANNEL_11;
  sConfig.Rank = 1;
  sConfig.SamplingTime = ADC_SAMPLETIME_84CYCLES;
  if (HAL_ADC_ConfigChannel(&hadc1, &sConfig) != HAL_OK)
  {
    Error_Handler();
  }
  /** Configure for the selected ADC regular channel its corresponding rank in the sequencer and its sample time.
  */
  sConfig.Channel = ADC_CHANNEL_12;
  sConfig.Rank = 2;
  if (HAL_ADC_ConfigChannel(&hadc1, &sConfig) != HAL_OK)
  {
    Error_Handler();
  }
  /** Configure for the selected ADC regular channel its corresponding rank in the sequencer and its sample time.
  */
  sConfig.Channel = ADC_CHANNEL_14;
  sConfig.Rank = 3;
  if (HAL_ADC_ConfigChannel(&hadc1, &sConfig) != HAL_OK)
  {
    Error_Handler();
  }
  /** Configure for the selected ADC regular channel its corresponding rank in the sequencer and its sample time.
  */
  sConfig.Channel = ADC_CHANNEL_15;
  sConfig.Rank = 4;
  if (HAL_ADC_ConfigChannel(&hadc1, &sConfig) != HAL_OK)
  {
    Error_Handler();
  }
  /** Configure for the selected ADC regular channel its corresponding rank in the sequencer and its sample time.
  */
  sConfig.Channel = ADC_CHANNEL_TEMPSENSOR;
  sConfig.Rank = 5;
  sConfig.SamplingTime = ADC_SAMPLETIME_480CYCLES;
  if (HAL_ADC_ConfigChannel(&hadc1, &sConfig) != HAL_OK)
  {
    Error_Handler();
  }
  /** Configure for the selected ADC regular channel its corresponding rank in the sequencer and its sample time.
  */
  sConfig.Channel = ADC_CHANNEL_VREFINT;
  sConfig.Rank = 6;
  if (HAL_ADC_ConfigChannel(&hadc1, &sConfig) != HAL_OK)
  {
    Error_Handler();
  }

}

static void MX_CAN1_Init(void)
{

  /* USER CODE BEGIN CAN1_Init 0 */
	m_trap = 456; // morse_trap(456);
  /* USER CODE END CAN1_Init 0 */

  hcan1.Instance = CAN1;
  hcan1.Init.Prescaler = 12;
  hcan1.Init.Mode = CAN_MODE_NORMAL;
  hcan1.Init.SyncJumpWidth = CAN_SJW_1TQ;
  hcan1.Init.TimeSeg1 = CAN_BS1_5TQ;
  hcan1.Init.TimeSeg2 = CAN_BS2_1TQ;
  hcan1.Init.TimeTriggeredMode = DISABLE;
  hcan1.Init.AutoBusOff = DISABLE;
  hcan1.Init.AutoWakeUp = DISABLE;
  hcan1.Init.AutoRetransmission = DISABLE;
  hcan1.Init.ReceiveFifoLocked = DISABLE;
  hcan1.Init.TransmitFifoPriority = DISABLE;
  if (HAL_CAN_Init(&hcan1) != HAL_OK)
  {
    Error_Handler();
  }

}

static void MX_I2C1_Init(void)
{

  /* USER CODE BEGIN I2C1_Init 0 */
	m_trap = 455; // morse_trap(455);
  /* USER CODE END I2C1_Init 0 */

  hi2c1.Instance = I2C1;
  hi2c1.Init.ClockSpeed = 100000;
  hi2c1.Init.DutyCycle = I2C_DUTYCYCLE_2;
  hi2c1.Init.OwnAddress1 = 0;
  hi2c1.Init.AddressingMode = I2C_ADDRESSINGMODE_7BIT;
  hi2c1.Init.DualAddressMode = I2C_DUALADDRESS_DISABLE;
  hi2c1.Init.OwnAddress2 = 0;
  hi2c1.Init.GeneralCallMode = I2C_GENERALCALL_DISABLE;
  hi2c1.Init.NoStretchMode = I2C_NOSTRETCH_DISABLE;
  if (HAL_I2C_Init(&hi2c1) != HAL_OK)
  {
    Error_Handler();
  }

}

static void MX_SPI2_Init(void)
{

  /* USER CODE BEGIN SPI2_Init 0 */
	m_trap = 454; // morse_trap(454);
  /* USER CODE END SPI2_Init 0 */

  /* SPI2 parameter configuration*/
  hspi2.Instance = SPI2;
  hspi2.Init.Mode = SPI_MODE_MASTER;
  hspi2.Init.Direction = SPI_DIRECTION_2LINES;
  hspi2.Init.DataSize = SPI_DATASIZE_8BIT;
  hspi2.Init.CLKPolarity = SPI_POLARITY_LOW;
  hspi2.Init.CLKPhase = SPI_PHASE_1EDGE;
  hspi2.Init.NSS = SPI_NSS_SOFT;
  hspi2.Init.BaudRatePrescaler = SPI_BAUDRATEPRESCALER_256;
  hspi2.Init.FirstBit = SPI_FIRSTBIT_MSB;
  hspi2.Init.TIMode = SPI_TIMODE_DISABLE;
  hspi2.Init.CRCCalculation = SPI_CRCCALCULATION_DISABLE;
  hspi2.Init.CRCPolynomial = 10;
  if (HAL_SPI_Init(&hspi2) != HAL_OK)
  {
    Error_Handler();
  }

}

static void MX_TIM1_Init(void)
{

  /* USER CODE BEGIN TIM1_Init 0 */
	m_trap = 453; // morse_trap(453);
  /* USER CODE END TIM1_Init 0 */

  TIM_ClockConfigTypeDef sClockSourceConfig = {0};
  TIM_MasterConfigTypeDef sMasterConfig = {0};
  TIM_OC_InitTypeDef sConfigOC = {0};
  TIM_BreakDeadTimeConfigTypeDef sBreakDeadTimeConfig = {0};

  htim1.Instance = TIM1;
  htim1.Init.Prescaler = 0;
  htim1.Init.CounterMode = TIM_COUNTERMODE_UP;
  htim1.Init.Period = 35000;
  htim1.Init.ClockDivision = TIM_CLOCKDIVISION_DIV1;
  htim1.Init.RepetitionCounter = 0;
  htim1.Init.AutoReloadPreload = TIM_AUTORELOAD_PRELOAD_DISABLE;
  if (HAL_TIM_Base_Init(&htim1) != HAL_OK)
  {
    Error_Handler();
  }
  sClockSourceConfig.ClockSource = TIM_CLOCKSOURCE_INTERNAL;
  if (HAL_TIM_ConfigClockSource(&htim1, &sClockSourceConfig) != HAL_OK)
  {
    Error_Handler();
  }
  if (HAL_TIM_PWM_Init(&htim1) != HAL_OK)
  {
    Error_Handler();
  }
  sMasterConfig.MasterOutputTrigger = TIM_TRGO_OC1REF;
  sMasterConfig.MasterSlaveMode = TIM_MASTERSLAVEMODE_DISABLE;
  if (HAL_TIMEx_MasterConfigSynchronization(&htim1, &sMasterConfig) != HAL_OK)
  {
    Error_Handler();
  }
  sConfigOC.OCMode = TIM_OCMODE_PWM1;
  sConfigOC.Pulse = 35001; //15700;
  sConfigOC.OCPolarity = TIM_OCPOLARITY_HIGH;
  sConfigOC.OCNPolarity = TIM_OCNPOLARITY_HIGH;
  sConfigOC.OCFastMode = TIM_OCFAST_DISABLE;
  sConfigOC.OCIdleState = TIM_OCIDLESTATE_RESET;
  sConfigOC.OCNIdleState = TIM_OCNIDLESTATE_RESET;
  if (HAL_TIM_PWM_ConfigChannel(&htim1, &sConfigOC, TIM_CHANNEL_1) != HAL_OK)
  {
    Error_Handler();
  }
  sBreakDeadTimeConfig.OffStateRunMode = TIM_OSSR_DISABLE;
  sBreakDeadTimeConfig.OffStateIDLEMode = TIM_OSSI_DISABLE;
  sBreakDeadTimeConfig.LockLevel = TIM_LOCKLEVEL_OFF;
  sBreakDeadTimeConfig.DeadTime = 0;
  sBreakDeadTimeConfig.BreakState = TIM_BREAK_DISABLE;
  sBreakDeadTimeConfig.BreakPolarity = TIM_BREAKPOLARITY_HIGH;
  sBreakDeadTimeConfig.AutomaticOutput = TIM_AUTOMATICOUTPUT_DISABLE;
  if (HAL_TIMEx_ConfigBreakDeadTime(&htim1, &sBreakDeadTimeConfig) != HAL_OK)
  {
    Error_Handler();
  }
  HAL_TIM_MspPostInit(&htim1);

}

static void MX_TIM2_Init(void)
{

  TIM_Encoder_InitTypeDef sConfig = {0};
  TIM_MasterConfigTypeDef sMasterConfig = {0};

  htim2.Instance = TIM2;
  htim2.Init.Prescaler = 0;
  htim2.Init.CounterMode = TIM_COUNTERMODE_UP;
  htim2.Init.Period = 4294967295;
  htim2.Init.ClockDivision = TIM_CLOCKDIVISION_DIV1;
  htim2.Init.AutoReloadPreload = TIM_AUTORELOAD_PRELOAD_DISABLE;
  sConfig.EncoderMode = TIM_ENCODERMODE_TI1;
  sConfig.IC1Polarity = TIM_ICPOLARITY_RISING;
  sConfig.IC1Selection = TIM_ICSELECTION_DIRECTTI;
  sConfig.IC1Prescaler = TIM_ICPSC_DIV1;
  sConfig.IC1Filter = 0;
  sConfig.IC2Polarity = TIM_ICPOLARITY_RISING;
  sConfig.IC2Selection = TIM_ICSELECTION_DIRECTTI;
  sConfig.IC2Prescaler = TIM_ICPSC_DIV1;
  sConfig.IC2Filter = 0;
  if (HAL_TIM_Encoder_Init(&htim2, &sConfig) != HAL_OK)
  {
    Error_Handler();
  }
  sMasterConfig.MasterOutputTrigger = TIM_TRGO_RESET;
  sMasterConfig.MasterSlaveMode = TIM_MASTERSLAVEMODE_DISABLE;
  if (HAL_TIMEx_MasterConfigSynchronization(&htim2, &sMasterConfig) != HAL_OK)
  {
    Error_Handler();
  }

}

static void MX_TIM3_Init(void)
{

  TIM_ClockConfigTypeDef sClockSourceConfig = {0};
  TIM_MasterConfigTypeDef sMasterConfig = {0};
  TIM_OC_InitTypeDef sConfigOC = {0};

  htim3.Instance = TIM3;
  htim3.Init.Prescaler = 0;
  htim3.Init.CounterMode = TIM_COUNTERMODE_UP;
  htim3.Init.Period = 1680;
  htim3.Init.ClockDivision = TIM_CLOCKDIVISION_DIV1;
  htim3.Init.AutoReloadPreload = TIM_AUTORELOAD_PRELOAD_DISABLE;
  if (HAL_TIM_Base_Init(&htim3) != HAL_OK)
  {
    Error_Handler();
  }
  sClockSourceConfig.ClockSource = TIM_CLOCKSOURCE_INTERNAL;
  if (HAL_TIM_ConfigClockSource(&htim3, &sClockSourceConfig) != HAL_OK)
  {
    Error_Handler();
  }
  if (HAL_TIM_OC_Init(&htim3) != HAL_OK)
  {
    Error_Handler();
  }
  sMasterConfig.MasterOutputTrigger = TIM_TRGO_RESET;
  sMasterConfig.MasterSlaveMode = TIM_MASTERSLAVEMODE_DISABLE;
  if (HAL_TIMEx_MasterConfigSynchronization(&htim3, &sMasterConfig) != HAL_OK)
  {
    Error_Handler();
  }
  sConfigOC.OCMode = TIM_OCMODE_TIMING;
  sConfigOC.Pulse = 0;
  sConfigOC.OCPolarity = TIM_OCPOLARITY_HIGH;
  sConfigOC.OCFastMode = TIM_OCFAST_DISABLE;
  if (HAL_TIM_OC_ConfigChannel(&htim3, &sConfigOC, TIM_CHANNEL_1) != HAL_OK)
  {
    Error_Handler();
  }

}

static void MX_TIM5_Init(void)
{

  TIM_ClockConfigTypeDef sClockSourceConfig = {0};
  TIM_MasterConfigTypeDef sMasterConfig = {0};
  TIM_OC_InitTypeDef sConfigOC = {0};

  htim5.Instance = TIM5;
  htim5.Init.Prescaler = 0;
  htim5.Init.CounterMode = TIM_COUNTERMODE_UP;
  htim5.Init.Period = 4294967295;
  htim5.Init.ClockDivision = TIM_CLOCKDIVISION_DIV1;
  htim5.Init.AutoReloadPreload = TIM_AUTORELOAD_PRELOAD_DISABLE;
  if (HAL_TIM_Base_Init(&htim5) != HAL_OK)
  {
    Error_Handler();
  }
  sClockSourceConfig.ClockSource = TIM_CLOCKSOURCE_INTERNAL;
  if (HAL_TIM_ConfigClockSource(&htim5, &sClockSourceConfig) != HAL_OK)
  {
    Error_Handler();
  }
  if (HAL_TIM_OC_Init(&htim5) != HAL_OK)
  {
    Error_Handler();
  }
  sMasterConfig.MasterOutputTrigger = TIM_TRGO_RESET;
  sMasterConfig.MasterSlaveMode = TIM_MASTERSLAVEMODE_DISABLE;
  if (HAL_TIMEx_MasterConfigSynchronization(&htim5, &sMasterConfig) != HAL_OK)
  {
    Error_Handler();
  }
  sConfigOC.OCMode = TIM_OCMODE_TIMING;
  sConfigOC.Pulse = 0;
  sConfigOC.OCPolarity = TIM_OCPOLARITY_HIGH;
  sConfigOC.OCFastMode = TIM_OCFAST_DISABLE;
  if (HAL_TIM_OC_ConfigChannel(&htim5, &sConfigOC, TIM_CHANNEL_1) != HAL_OK)
  {
    Error_Handler();
  }

}

static void MX_TIM9_Init(void)
{

  TIM_ClockConfigTypeDef sClockSourceConfig = {0};
  TIM_OC_InitTypeDef sConfigOC = {0};

  htim9.Instance = TIM9;
  htim9.Init.Prescaler = 0;
  htim9.Init.CounterMode = TIM_COUNTERMODE_UP;
  htim9.Init.Period = 1680;
  htim9.Init.ClockDivision = TIM_CLOCKDIVISION_DIV1;
  htim9.Init.AutoReloadPreload = TIM_AUTORELOAD_PRELOAD_DISABLE;
  if (HAL_TIM_Base_Init(&htim9) != HAL_OK)
  {
    Error_Handler();
  }
  sClockSourceConfig.ClockSource = TIM_CLOCKSOURCE_INTERNAL;
  if (HAL_TIM_ConfigClockSource(&htim9, &sClockSourceConfig) != HAL_OK)
  {
    Error_Handler();
  }
  if (HAL_TIM_PWM_Init(&htim9) != HAL_OK)
  {
    Error_Handler();
  }
  if (HAL_TIM_OnePulse_Init(&htim9, TIM_OPMODE_SINGLE) != HAL_OK)
  {
    Error_Handler();
  }
  sConfigOC.OCMode = TIM_OCMODE_PWM1;
  sConfigOC.Pulse = 504;
  sConfigOC.OCPolarity = TIM_OCPOLARITY_HIGH;
  sConfigOC.OCFastMode = TIM_OCFAST_DISABLE;
  if (HAL_TIM_PWM_ConfigChannel(&htim9, &sConfigOC, TIM_CHANNEL_1) != HAL_OK)
  {
    Error_Handler();
  }
  HAL_TIM_MspPostInit(&htim9);

}

static void MX_USART2_UART_Init(void)
{

  /* USER CODE BEGIN USART2_Init 0 */
	m_trap = 452; // morse_trap(452);
  /* USER CODE END USART2_Init 0 */

  huart2.Instance = USART2;
  huart2.Init.BaudRate = 2000000;
  huart2.Init.WordLength = UART_WORDLENGTH_8B;
  huart2.Init.StopBits = UART_STOPBITS_1;
  huart2.Init.Parity = UART_PARITY_NONE;
  huart2.Init.Mode = UART_MODE_TX_RX;
  huart2.Init.HwFlowCtl = UART_HWCONTROL_NONE;
  huart2.Init.OverSampling = UART_OVERSAMPLING_16;
  if (HAL_UART_Init(&huart2) != HAL_OK)
  {
    Error_Handler();
  }

}

static void MX_USART3_UART_Init(void)
{

  /* USER CODE BEGIN USART3_Init 0 */
	m_trap = 451; // morse_trap(451);
  /* USER CODE END USART3_Init 0 */

  huart3.Instance = USART3;
  huart3.Init.BaudRate = 115200;
  huart3.Init.WordLength = UART_WORDLENGTH_8B;
  huart3.Init.StopBits = UART_STOPBITS_1;
  huart3.Init.Parity = UART_PARITY_NONE;
  huart3.Init.Mode = UART_MODE_TX_RX;
  huart3.Init.HwFlowCtl = UART_HWCONTROL_NONE;
  huart3.Init.OverSampling = UART_OVERSAMPLING_16;
  if (HAL_UART_Init(&huart3) != HAL_OK)
  {
    Error_Handler();
  }

}

static void MX_USART6_UART_Init(void)
{

  /* USER CODE BEGIN USART6_Init 0 */
	m_trap = 458; // morse_trap(458);
  /* USER CODE END USART6_Init 0 */

  huart6.Instance = USART6;
  huart6.Init.BaudRate = 9600;
  huart6.Init.WordLength = UART_WORDLENGTH_8B;
  huart6.Init.StopBits = UART_STOPBITS_1;
  huart6.Init.Parity = UART_PARITY_NONE;
  huart6.Init.Mode = UART_MODE_TX_RX;
  huart6.Init.HwFlowCtl = UART_HWCONTROL_NONE;
  huart6.Init.OverSampling = UART_OVERSAMPLING_16;
  if (HAL_UART_Init(&huart6) != HAL_OK)
  {
    Error_Handler();
  }

}

static void MX_DMA_Init(void)
{

  /* DMA controller clock enable */
  __HAL_RCC_DMA1_CLK_ENABLE();
  __HAL_RCC_DMA2_CLK_ENABLE();

  /* DMA interrupt init */
  /* DMA1_Stream0_IRQn interrupt configuration */
  HAL_NVIC_SetPriority(DMA1_Stream0_IRQn, 8, 0);
  HAL_NVIC_EnableIRQ(DMA1_Stream0_IRQn);
  /* DMA1_Stream1_IRQn interrupt configuration */
  HAL_NVIC_SetPriority(DMA1_Stream1_IRQn, 10, 0);
  HAL_NVIC_EnableIRQ(DMA1_Stream1_IRQn);
  /* DMA1_Stream3_IRQn interrupt configuration */
  HAL_NVIC_SetPriority(DMA1_Stream3_IRQn, 10, 0);
  HAL_NVIC_EnableIRQ(DMA1_Stream3_IRQn);
  /* DMA1_Stream5_IRQn interrupt configuration */
  HAL_NVIC_SetPriority(DMA1_Stream5_IRQn, 6, 0);
  HAL_NVIC_EnableIRQ(DMA1_Stream5_IRQn);
  /* DMA1_Stream6_IRQn interrupt configuration */
  HAL_NVIC_SetPriority(DMA1_Stream6_IRQn, 6, 0);
  HAL_NVIC_EnableIRQ(DMA1_Stream6_IRQn);
  /* DMA1_Stream7_IRQn interrupt configuration */
  HAL_NVIC_SetPriority(DMA1_Stream7_IRQn, 12, 0);
  HAL_NVIC_EnableIRQ(DMA1_Stream7_IRQn);
  /* DMA2_Stream0_IRQn interrupt configuration */
  HAL_NVIC_SetPriority(DMA2_Stream0_IRQn, 6, 0);
  HAL_NVIC_EnableIRQ(DMA2_Stream0_IRQn);
  /* DMA2_Stream1_IRQn interrupt configuration */
  HAL_NVIC_SetPriority(DMA2_Stream1_IRQn, 11, 0);
  HAL_NVIC_EnableIRQ(DMA2_Stream1_IRQn);
  /* DMA2_Stream6_IRQn interrupt configuration */
  HAL_NVIC_SetPriority(DMA2_Stream6_IRQn, 11, 0);
  HAL_NVIC_EnableIRQ(DMA2_Stream6_IRQn);

}

static void MX_GPIO_Init(void)
{
  GPIO_InitTypeDef GPIO_InitStruct = {0};

  /* GPIO Ports Clock Enable */
  __HAL_RCC_GPIOE_CLK_ENABLE();
  __HAL_RCC_GPIOH_CLK_ENABLE();
  __HAL_RCC_GPIOC_CLK_ENABLE();
  __HAL_RCC_GPIOA_CLK_ENABLE();
  __HAL_RCC_GPIOB_CLK_ENABLE();
  __HAL_RCC_GPIOD_CLK_ENABLE();

  /*Configure GPIO pin Output Level */
  HAL_GPIO_WritePin(GPIOE, Beeper_Drive_Pin|JUMP_OUT_Pin, GPIO_PIN_RESET);

  /*Configure GPIO pin Output Level */
  HAL_GPIO_WritePin(GPIOA, GPIO_PIN_5, GPIO_PIN_RESET);

  /*Configure GPIO pin Output Level */
  HAL_GPIO_WritePin(GPIOB, Stepper__DR__direction_Pin|Stepper__MF_not_enable_Pin|SPI2_NSS__CK_Pin, GPIO_PIN_RESET);

  /*Configure GPIO pin Output Level */
  HAL_GPIO_WritePin(GPIOD, LED_GREEN_Pin|LED_ORANGE_Pin|LED_RED_Pin|LED_BLUE_Pin, GPIO_PIN_RESET);

  /*Configure GPIO pin : Beeper_Drive_Pin */
  GPIO_InitStruct.Pin = Beeper_Drive_Pin;
  GPIO_InitStruct.Mode = GPIO_MODE_OUTPUT_PP;
  GPIO_InitStruct.Pull = GPIO_NOPULL;
  GPIO_InitStruct.Speed = GPIO_SPEED_FREQ_LOW;
  HAL_GPIO_Init(Beeper_Drive_GPIO_Port, &GPIO_InitStruct);

  /*Configure GPIO pin : PA5 */
  GPIO_InitStruct.Pin = GPIO_PIN_5;
  GPIO_InitStruct.Mode = GPIO_MODE_OUTPUT_PP;
  GPIO_InitStruct.Pull = GPIO_NOPULL;
  GPIO_InitStruct.Speed = GPIO_SPEED_FREQ_LOW;
  HAL_GPIO_Init(GPIOA, &GPIO_InitStruct);

  /*Configure GPIO pin : Stepper__DR__direction_Pin */
  GPIO_InitStruct.Pin = Stepper__DR__direction_Pin;
  GPIO_InitStruct.Mode = GPIO_MODE_OUTPUT_PP;
  GPIO_InitStruct.Pull = GPIO_NOPULL;
  GPIO_InitStruct.Speed = GPIO_SPEED_FREQ_MEDIUM;
  HAL_GPIO_Init(Stepper__DR__direction_GPIO_Port, &GPIO_InitStruct);

  /*Configure GPIO pin : Stepper__MF_not_enable_Pin */
  GPIO_InitStruct.Pin = Stepper__MF_not_enable_Pin;
  GPIO_InitStruct.Mode = GPIO_MODE_OUTPUT_PP;
  GPIO_InitStruct.Pull = GPIO_NOPULL;
  GPIO_InitStruct.Speed = GPIO_SPEED_FREQ_LOW;
  HAL_GPIO_Init(Stepper__MF_not_enable_GPIO_Port, &GPIO_InitStruct);

  /*Configure GPIO pins : LimitSw_inside_NO_Pin LimitSw_inside_NC_Pin LimitSw_outside_NO_Pin LimitSw_outside_NC_Pin
                           LimitSw_index_NO_Pin LimitSw_index_NC_Pin */
  GPIO_InitStruct.Pin = LimitSw_inside_NO_Pin|LimitSw_inside_NC_Pin|LimitSw_outside_NO_Pin|LimitSw_outside_NC_Pin
                          |LimitSw_index_NO_Pin|LimitSw_index_NC_Pin;
  GPIO_InitStruct.Mode = GPIO_MODE_IT_RISING;
  GPIO_InitStruct.Pull = GPIO_PULLUP;
  HAL_GPIO_Init(GPIOE, &GPIO_InitStruct);

  /*Configure GPIO pin : SPI2_NSS__CK_Pin */
  GPIO_InitStruct.Pin = SPI2_NSS__CK_Pin;
  GPIO_InitStruct.Mode = GPIO_MODE_OUTPUT_PP;
  GPIO_InitStruct.Pull = GPIO_PULLUP;
  GPIO_InitStruct.Speed = GPIO_SPEED_FREQ_MEDIUM;
  HAL_GPIO_Init(SPI2_NSS__CK_GPIO_Port, &GPIO_InitStruct);

  /*Configure GPIO pins : LED_GREEN_Pin LED_ORANGE_Pin LED_RED_Pin LED_BLUE_Pin */
  GPIO_InitStruct.Pin = LED_GREEN_Pin|LED_ORANGE_Pin|LED_RED_Pin|LED_BLUE_Pin;
  GPIO_InitStruct.Mode = GPIO_MODE_OUTPUT_PP;
  GPIO_InitStruct.Pull = GPIO_NOPULL;
  GPIO_InitStruct.Speed = GPIO_SPEED_FREQ_LOW;
  HAL_GPIO_Init(GPIOD, &GPIO_InitStruct);

  /*Configure GPIO pin : JUMP_OUT_Pin */
  GPIO_InitStruct.Pin = JUMP_OUT_Pin;
  GPIO_InitStruct.Mode = GPIO_MODE_OUTPUT_PP;
  GPIO_InitStruct.Pull = GPIO_NOPULL;
  GPIO_InitStruct.Speed = GPIO_SPEED_FREQ_MEDIUM;
  HAL_GPIO_Init(JUMP_OUT_GPIO_Port, &GPIO_InitStruct);

  /*Configure GPIO pin : JUMP_IN_Pin */
  GPIO_InitStruct.Pin = JUMP_IN_Pin;
  GPIO_InitStruct.Mode = GPIO_MODE_INPUT;
  GPIO_InitStruct.Pull = GPIO_PULLDOWN;
  HAL_GPIO_Init(JUMP_IN_GPIO_Port, &GPIO_InitStruct);

  /* EXTI interrupt init*/
  HAL_NVIC_SetPriority(EXTI15_10_IRQn, 11, 0);
  HAL_NVIC_EnableIRQ(EXTI15_10_IRQn);

}

/* USER CODE BEGIN 4 */
// LCD msg: Main
//
static struct LCDMSGSET lcdi2cfunc1;
  #ifdef TWOCALLSWITHONEARGUMENT
static struct LCDMSGSET lcdi2cfunc2;
static struct LCDMSGSET lcdi2cfunc3;
  #else
static struct LCDMSGSET lcdi2cfunc4;
  #endif
//                                                                       "12345678901234567890"
static void lcdi2cmsgm1 (union LCDSETVAR u){lcdi2cputs  (&punitd4x20,0,0,"stpLVLWD 20201115 09");}
  #ifdef TWOCALLSWITHONEARGUMENT
static void lcdi2cmsgM1a(union LCDSETVAR u){lcdi2cprintf(&punitd4x20,DMOCSPDTQ, 0,"S%6i  ",   u.u32);}
static void lcdi2cmsgM1b(union LCDSETVAR u){lcdi2cprintf(&punitd4x20,DMOCSPDTQ, 9,"T%6.1f  ",u.f);}
  #else
static void lcdi2cmsgM1c(union LCDSETVAR u){
  if ((lcdcontext & LCDX_CNTR) == 0) // Skip if Contactor is in Fault: do not overwrite Contactor error msg
  lcdi2cprintf(&punitd4x20,DMOCSPDTQ, 0,"S%6i   T%6.1f  ",u.u32two[0],u.ftwo[1]);}
  #endif
static struct LCDMSGSET lcdi2cfunc5;
static void lcdi2cmsgMstep (union LCDSETVAR u){lcdi2cprintf(&punitd4x20,DMOCSPDTQ, 0,"SPS%6i RPM %6.1f  ",u.u32two[0],u.ftwo[1]);}
static void lcdi2cmsgMstepx(union LCDSETVAR u){lcdi2cprintf(&punitd4x20,DMOCSPDTQ, 0,"SPS%6i RPMx%6.1f  ",u.u32two[0],u.ftwo[1]);}

// LCD UART msg
//struct SERIALSENDTASKBCB* pbuflcd;

/* USER CODE END 4 */

/* USER CODE BEGIN Header_StartDefaultTask */
/**
  * @brief  Function implementing the defaultTask thread.
  * @param  argument: Not used
  * @retval None
  */
// ################################################################################
// ######### DEFAULT TASK #########################################################
// ################################################################################
/* USER CODE END Header_StartDefaultTask */
void StartDefaultTask(void const * argument)
{
  /* USER CODE BEGIN 5 */

osDelay(0); // Debugging HardFault

/* Select code for testing/monitoring by uncommenting #defines */
//#define DISPLAYSTACKUSAGEFORTASKS
//#define SHOWEXTENDEDSUMSOFADCRAWREADINGS
//#define SHOWSUMSOFADCRAWREADINGS
//#define SHOWINCREASINGAVERAGEOFADCRAWREADINGS
#define SHOWSERIALPARALLELSTUFF
//#define STARTUPCHASINGLEDS
//#define TESTBEEPER
//#define SENDCANTESTMSGSINABURST
//#define SHOWADCCOMMONCOMPUTATIONS
//#define DMOCTESTS
//#define CONTROLV1DEBUG
//#define STEPPERSHOW

	#define DEFAULTTSKBIT00	(1 << 0)  // Task notification bit for sw timer: stackusage
	#define DEFAULTTSKBIT01	(1 << 1)  // Task notification bit for sw timer: something else

	/* A notification copies the internal notification word to this. */
	uint32_t noteval = 0;    // Receives notification word upon an API notify

	/* notification bits processed after a 'Wait. */
	uint32_t noteused = 0;

	struct SERIALSENDTASKBCB* pbuf1 = getserialbuf(&HUARTMON,96);
	if (pbuf1 == NULL) morse_trap(11);

	struct SERIALSENDTASKBCB* pbuf3 = getserialbuf(&HUARTMON,96);
	if (pbuf3 == NULL) morse_trap(13);

	struct SERIALSENDTASKBCB* pbuf2 = getserialbuf(&HUARTMON,96);
	if (pbuf2 == NULL) morse_trap(12);

	struct SERIALSENDTASKBCB* pbuf4 = getserialbuf(&HUARTMON,96);
	if (pbuf4 == NULL) morse_trap(12);

  /* LCD I2C msgs used in this task. */
  // Wait for LcdTask to instantiate 4x20 #1 unit. */
  uint8_t loopctr = 0;
  while ((punitd4x20 == NULL) && (loopctr++ < 10)) osDelay(10);
      if (punitd4x20 == NULL) morse_trap(2326);

  // Initial "splash:" msg on line 1 of lcdi2c 4x20 #1 display
  lcdi2cfunc1.ptr = lcdi2cmsgm1;

  if (LcdmsgsetTaskQHandle == NULL) morse_trap(2323);
    xQueueSendToBack(LcdmsgsetTaskQHandle, &lcdi2cfunc1, 0);

  // STEPPERSHOW
  lcdi2cfunc5.ptr = lcdi2cmsgMstep;

  // Get buffers and partially initialize for later use.
#ifdef TWOCALLSWITHONEARGUMENT
  lcdi2cfunc2.ptr = lcdi2cmsgM1a;
  lcdi2cfunc3.ptr = lcdi2cmsgM1b;
#else
// One call with two arguments
  lcdi2cfunc4.ptr = lcdi2cmsgM1c;
#endif

#ifdef DISPLAYSTACKUSAGEFORTASKS
	int ctr = 0; // Running count
	uint32_t heapsize;
	uint32_t showctr = 0;
	uint32_t t1_DSUFT; // DTW time
	uint32_t t2_DSUFT;
#endif

#ifdef SENDCANTESTMSGSINABURST
	/* Test CAN msg */
	struct CANTXQMSG testtx;
	testtx.pctl = pctl0;
	testtx.can.id = 0xc2200000;
	testtx.can.dlc = 8;
	int i;
	for (i = 0; i < 8; i++)
		testtx.can.cd.uc[i] = 0x30 + i;
	testtx.maxretryct = 8;
	testtx.bits = 0;
#endif

HAL_GPIO_TogglePin(GPIOD,GPIO_PIN_15); // BLUE LED

#ifdef SHOWSUMSOFADCRAWREADINGS
extern uint32_t adcsumdb[ADC1IDX_ADCSCANSIZE]; // debug
extern uint32_t adcdbctr;    // debug
uint32_t adcdbctr_prev = adcdbctr;
uint16_t hdrctr = 999;
#endif

#ifdef SHOWEXTENDEDSUMSOFADCRAWREADINGS
uint16_t idx_xsum_prev = 0;
uint16_t hdrctr2 = 999;
#endif

#ifdef SHOWINCREASINGAVERAGEOFADCRAWREADINGS
float  fxxsum[ADC1IDX_ADCSCANSIZE];
float ftmp;
uint64_t xxsum[ADC1IDX_ADCSCANSIZE];
uint32_t ravectr = 0;
float frecip;
uint16_t idx_xxsum_prev = 0;
uint16_t hdrctr3 = 999;
uint8_t ix;
for (ix = 0; ix < ADC1IDX_ADCSCANSIZE; ix++) xxsum[ix] = 0;
#endif

#ifdef  SHOWSERIALPARALLELSTUFF
uint32_t spispctr_prev = 0;
#endif

#ifdef STARTUPCHASINGLEDS
#include "calib_control_lever.h"
struct LEDREQ spiledx;
spiledx.bitnum = 0; // Start with bit 0
struct LEDREQ spiledx_prev;
spiledx_prev.bitnum = 15; // Sart with previous bit 15
uint8_t chasectr = 0; // Counter for slowing down output rate
#endif

#ifdef TESTBEEPER
struct BEEPQ beepqtest;
beepqtest.duron  = 100;
beepqtest.duroff = 50;
beepqtest.repct  = 2;
//	HAL_TIM_PWM_Start(&htim1, TIM_CHANNEL_1);
#endif

#ifdef CONTROLV1DEBUG
uint16_t hdrctr = 0;

#endif

/* Purpose: flag to have other task wait before 'for' loop. */
lcdflag = 1;

/* Countdown timer for various display speeds. */
uint16_t slowtimectr = 0; // Approx 1/sec
uint16_t medtimectr = 0;  // Approx 8/sec

uint8_t ratepace = 0;

//osDelay(1);
	xTimerChangePeriod( defaultTaskTimerHandle  ,pdMS_TO_TICKS(64),0);
// ===== BEGIN FOR LOOP ==============================

	for ( ;; )
	{
		xTaskNotifyWait(noteused, 0, &noteval, portMAX_DELAY);
		noteused = 0;
		if ((noteval & DEFAULTTSKBIT00) != 0)
		{
			noteused |= DEFAULTTSKBIT00;
// ================= Higest rate =======================================
			/* Check each LED until CL calibration ends. */
			led_chasing();

    ratepace += 1;
    if (ratepace > 2) // Slow down LCD output rate
    {
      ratepace = 0;

			/* Update CL position on LCD after CL calibration ends. */
			lcdout();

			/* Generate LCD msg for speed actual and commanded torque. */
			if (flag_clcalibed != 0)
			{
//HAL_GPIO_TogglePin(GPIOD, LED_GREEN_Pin); // GREEN

#ifndef STEPPERSHOW
#ifdef TWOCALLSWITHONEARGUMENT
        // LCD I2C: two values requires two calls
        lcdi2cfunc2.u.u32 = dmocctl[DMOC_SPEED].speedact; // Value that is passed to function
        if (LcdmsgsetTaskQHandle != NULL)
            xQueueSendToBack(LcdmsgsetTaskQHandle, &lcdi2cfunc2, 0);

        lcdi2cfunc3.u.f = dmocctl[DMOC_SPEED].ftorquereq; // Value that is passed to function
        if (LcdmsgsetTaskQHandle != NULL)
            xQueueSendToBack(LcdmsgsetTaskQHandle, &lcdi2cfunc3, 0);
#else
        lcdi2cfunc4.u.u32two[0] = dmocctl[DMOC_SPEED].speedact; // Value that is passed to function
        lcdi2cfunc4.u.ftwo[1]   = dmocctl[DMOC_SPEED].ftorquereq; // Value that is passed to function
        if (LcdmsgsetTaskQHandle != NULL)
            xQueueSendToBack(LcdmsgsetTaskQHandle, &lcdi2cfunc4, 0);

#endif
#endif
			}

			/* LCD output from queue pointers. */
			lcdmsg_poll();

#ifdef STEPPERSHOW
      lcdi2cfunc5.u.ftwo[1] = stepperstuff.speedcmdf*((((100000/2000)*0.0006)));
      if (gevcufunction.stepperdrtoggle != 0)
      {
        lcdi2cfunc5.u.ftwo[1] = -lcdi2cfunc5.u.ftwo[1];
      }

      if (gevcufunction.stepperclpostoggle == 0)
      {
        lcdi2cfunc5.ptr = lcdi2cmsgMstep;
      }
      else
      {
        lcdi2cfunc5.ptr = lcdi2cmsgMstepx;
      }

      if (LcdmsgsetTaskQHandle != NULL)
        xQueueSendToBack(LcdmsgsetTaskQHandle, &lcdi2cfunc5, 0);

      lcdi2cfunc5.u.u32two[0] = stepperstuff.speedcmdi;
uint16_t pbpin = GPIOB->ODR;
    yprintf(&pbuf4,"\n\rINC%6u| RPM %6.1f| Pay0 %04x",stepperstuff.speedcmdi,lcdi2cfunc5.u.ftwo[1],gevcufunction.canmsg[CID_GEVCUR_TST_STEPCMD].can.cd.uc[0]);

#endif
    }

#ifdef DMOCTESTS
	yprintf(&pbuf1,"\n\rSTATE:dmoc:act: %X new: %X : rep: %X :op: %X",
         dmocctl[DMOC_SPEED].dmocstateact,
         dmocctl[DMOC_SPEED].dmocstatenew,
         dmocctl[DMOC_SPEED].dmocstaterep,
         dmocctl[DMOC_SPEED].dmocopstate);
#endif

#ifdef CONTROLV1DEBUG
	hdrctr += 1;
	if (hdrctr > 16)
	{
		hdrctr = 0;
		yprintf(&pbuf4,"\n\rdesired   act  err intgrtr torqreq state");
	}

	yprintf(&pbuf2,"\n\r%7.1f %5i %4.1f %7.1f %7.1f  %01X",
		clv1.dsrdspd,	                 /* Desired speed */
		dmocctl[DMOC_SPEED].speedact,   /* Actual speed */
		clv1.spderr,	                 /* Speed error   */
		clv1.intgrtr,                   /* PI integrator */
		dmocctl[DMOC_SPEED].ftorquereq, /* Torque requested */
		dmocctl[DMOC_SPEED].dmocopstate);/* DMOC state actual*/
#endif

// ================== SLOW ==============================================
/* Countdown timer notifications. */
			slowtimectr += 1;
			if (slowtimectr >= 16)
			{
				slowtimectr = 0;

#ifdef DISPLAYSTACKUSAGEFORTASKS
			/* Display the amount of unused stack space for tasks. */
t1_DSUFT = DTWTIME;
			showctr += 1;
/* 'for' is to test doing all scans at one timer tick. */
for (showctr = 0; showctr < 13; showctr++)
{
				switch (showctr)
				{
/* Cycle through the tasks. */
case  0: stackwatermark_show(defaultTaskHandle,&pbuf1,"defaultTask--");break;
case  1: stackwatermark_show(SerialTaskHandle ,&pbuf2,"SerialTask---");break;
case  2: stackwatermark_show(CanTxTaskHandle  ,&pbuf3,"CanTxTask----");break;
case  3: stackwatermark_show(MailboxTaskHandle,&pbuf4,"MailboxTask--");break;
case  4: stackwatermark_show(ADCTaskHandle    ,&pbuf1,"ADCTask------");break;
case  5: stackwatermark_show(SerialTaskReceiveHandle,&pbuf2,"SerialRcvTask");break;
case  6: stackwatermark_show(GatewayTaskHandle,&pbuf3,"GatewayTask--");break;
//case  7: stackwatermark_show(CdcTxTaskSendHandle,&pbuf4,"CdcTxTask----");break;
case 7: break;
case  8: stackwatermark_show(SpiOutTaskHandle, &pbuf1,"SpiOutTask---");break;
case  9: stackwatermark_show(GevcuTaskHandle,  &pbuf2,"GevcuTask----");break;
case 10: stackwatermark_show(BeepTaskHandle,   &pbuf3,"BeepTask-----");break;
case 11: stackwatermark_show(LEDTaskHandle,    &pbuf4,"LEDTask------");break;

case 12:	heapsize = xPortGetFreeHeapSize(); // Heap usage (and test fp working.
			yprintf(&pbuf1,"\n\rGetFreeHeapSize: total: %i free %i %3.1f%% used: %i",configTOTAL_HEAP_SIZE, heapsize,\
				100.0*(float)heapsize/configTOTAL_HEAP_SIZE,(configTOTAL_HEAP_SIZE-heapsize)); break;
default: showctr=0; yprintf(&pbuf1,"\n\r%4i Unused Task stack space--", ctr++); break;
				}
}
t2_DSUFT = DTWTIME;
yprintf(&pbuf2,"\n\rDTW DUR: %d",t2_DSUFT - t1_DSUFT);

#endif

#ifdef TESTBEEPER
			xQueueSendToBack(BeepTaskQHandle,&beepqtest,portMAX_DELAY);

#endif

#ifdef  SENDCANTESTMSGSINABURST
			/* ==== CAN MSG sending test ===== */
			/* Place test CAN msg to send on queue in a burst. */
			/* Note: an odd makes the LED flash since it toggles on each msg. */
uint16_t ib;
			for (ib = 0; ib < 7; ib++)
				xQueueSendToBack(CanTxQHandle,&testtx,portMAX_DELAY);
#endif

#ifdef DEBUGGINGCDCREADINGFROMPC
/* Debugging CDC reading from PC */
extern uint32_t dbuggateway1;
extern uint32_t dbcdcrx;
extern uint32_t dblen;
extern uint32_t cdcifctr;
extern uint32_t dbrxbuff;
yprintf(&pbuf2,"\n\rdbuggateway1: %d dbcdcrx: %d dblen: %d cdcifctr: %d dbrxbuff: %d", dbuggateway1,dbcdcrx,dblen,cdcifctr,dbrxbuff);
#endif
  			}
// ================= Moderate ===================================
/* Countdown timer notifications. */
			medtimectr += 1;
			if (medtimectr >= 4)
			{
				medtimectr = 0;

		HAL_GPIO_TogglePin(GPIOD,GPIO_PIN_15); // BLUE LED

#ifdef SHOWSERIALPARALLELSTUFF
			/* SPI serial-parallel hw testing. */
			yprintf(&pbuf3,"\n\rspi ctr: %4d wr: %04X rd: %04X",(spispctr - spispctr_prev),spisp_wr[0].u16,spisp_rd[0].u16);
			spispctr_prev = spispctr; // Running count of spi interrupts

//			yprintf(&pbuf2,"\tcurpos %5.1f %5d %5d",clfunc.curpos,adc1.chan[0].sum,adc1.abs[0].adcfil);

//extern struct SWITCHPTR swpair_safeactive;
extern struct SWITCHPTR* psw_cl_fs_no;
extern struct SWITCHPTR* psw_cl_rst_n0;
extern uint16_t sr1;
extern uint16_t srdiff1;
			yprintf(&pbuf4,"\tcurpos %5.1f %d %d %d %d %d %d  %d %d %04X %04X",clfunc.curpos,
					gevcufunction.psw[PSW_ZTENSION]->db_on,
					gevcufunction.psw[PSW_ZODOMTR]->db_on,
					gevcufunction.psw[PSW_PB_PREP]->db_on,
					gevcufunction.psw[PSW_PB_ARM]->db_on,
					psw_cl_fs_no->db_on,
					psw_cl_rst_n0->db_on,
					gevcufunction.psw[PSW_PR_SAFE]->db_on,
					gevcufunction.psw[PSW_PR_SAFE]->on,
					sr1, srdiff1);
#endif

//#define SHOWMAILBOXGEVCU07
#ifdef SHOWMAILBOXGEVCU07
extern struct MAILBOXCAN* pdbg07mbx;
yprintf(&pbuf3,"\n\rCONT %4d %08X %02X",pdbg07mbx->ctr,pdbg07mbx->ncan.can.id,pdbg07mbx->ncan.can.cd.uc[0]);
#endif

#ifdef STARTUPCHASINGLEDS
				if (flag_clcalibed == 0)
				{
					chasectr += 1;
					if (chasectr > 2)
					{
				chasectr = 0;
				/* Send a lit LED down the row, over and over. */
				spiledx.mode = LED_ON; // Turn current LED on
				xQueueSendToBack(LEDTaskQHandle,&spiledx,portMAX_DELAY);

				spiledx_prev.mode = LED_OFF; // Turn previous LED off
				xQueueSendToBack(LEDTaskQHandle,&spiledx_prev,portMAX_DELAY);

				spiledx_prev = spiledx; // Update previous
				spiledx.bitnum += 1;    // Advance new
				if (spiledx.bitnum > 15) spiledx.bitnum = 0;
					}
				}
				// When Calibration complete turn off the lit LED
				if (flag_clcalibed == 1)
				{
			flag_clcalibed = 2;
			spiledx_prev.mode = LED_OFF; // Turn previous LED off
			xQueueSendToBack(LEDTaskQHandle,&spiledx_prev,portMAX_DELAY);
				}
#endif

#ifdef SHOWADCCOMMONCOMPUTATIONS
uint32_t dmact_prev = adcommon.dmact;
extern volatile uint32_t adcdbg2;
			yprintf(&pbuf4,"\n\rADC: Vdd: %7.4f %8.4f   Temp: %6.1f %6.1f %i",adcommon.fvdd,adcommon.fvddfilt,adcommon.degC,adcommon.degCfilt,(adcommon.dmact-dmact_prev));
			dmact_prev = adcommon.dmact;

//			yprintf(&pbuf4,"\n\rInternal ref:   %d %d %d\n\r",adc1.chan[ADC1IDX_INTERNALVREF].sum/ADC1DMANUMSEQ, adcommon.ivdd, adcdbg2);

			yprintf(&pbuf1,"\n\rCalibrated: vref: %6.4f",adc1.common.fvref);
#endif

#ifdef SHOWSUMSOFADCRAWREADINGS
				hdrctr += 1;
				if (hdrctr >= 16) // Periodic print header
				{
					hdrctr = 0;
yprintf(&pbuf1,"\n\r     count           CL     12V    5V    spare  temp   vref");
				}
yprintf(&pbuf2,"\n\rctr: %5d adcsum: %6d %6d %6d %6d %6d %6d",(adcdbctr-adcdbctr_prev),adcsumdb[0],adcsumdb[1],adcsumdb[2],adcsumdb[3],adcsumdb[4],adcsumdb[5]);
		adcdbctr_prev = adcdbctr;
#endif

#ifdef SHOWEXTENDEDSUMSOFADCRAWREADINGS
				if (adc1.idx_xsum != idx_xsum_prev)
				{
					hdrctr2 += 1;
					if (hdrctr2 >= 16) // Periodic print header
					{
						hdrctr2 = 0;
yprintf(&pbuf3,"\n\r     count           CL     12V    5V    spare  temp   vref");
				}
				idx_xsum_prev = adc1.idx_xsum;
				yprintf(&pbuf3,"\n\rctr: %5d  exsum: %6.0f %6.0f %6.0f %6.0f %6.0f %6.0f",hdrctr2,
					(float)adc1.chan[0].xsum[1]*(1.0/(float)ADCEXTENDSUMCT),
					(float)adc1.chan[1].xsum[1]*(1.0/(float)ADCEXTENDSUMCT),
					(float)adc1.chan[2].xsum[1]*(1.0/(float)ADCEXTENDSUMCT),
					(float)adc1.chan[3].xsum[1]*(1.0/(float)ADCEXTENDSUMCT),
					(float)adc1.chan[4].xsum[1]*(1.0/(float)ADCEXTENDSUMCT),
					(float)adc1.chan[5].xsum[1]*(1.0/(float)ADCEXTENDSUMCT)	);
				}
#endif

#ifdef SHOWINCREASINGAVERAGEOFADCRAWREADINGS
				if (adc1.idx_xsum != idx_xxsum_prev)
				{
					hdrctr3 += 1;
					if (hdrctr3 >= 16) // Periodic print header
					{
						hdrctr3 = 0;
yprintf(&pbuf3,"\n\r     count           CL     12V    5V    spare  temp   vref");
					}
					idx_xxsum_prev = adc1.idx_xsum;
					ravectr += 1;
					frecip =  (1.0/((float)ADCEXTENDSUMCT * (float)ravectr));

					for (ix = 0; ix < ADC1IDX_ADCSCANSIZE; ix++)
					{
						xxsum[ix] += adc1.chan[ix].xsum[1];
						ftmp = xxsum[ix];
						fxxsum[ix] = ftmp * frecip;
					}
yprintf(&pbuf4,"\n\rctr: %5d incave: %6.0f %6.0f %6.0f %6.0f %6.0f %6.0f",
		ravectr,fxxsum[0],fxxsum[1],fxxsum[2],fxxsum[3],fxxsum[4],fxxsum[5]);
				}
#endif
			}
	  	}
	}
  /* USER CODE END 5 */
}

/* CallbackdefaultTaskTimer function */
void CallbackdefaultTaskTimer(void const * argument)
{
  /* USER CODE BEGIN CallbackdefaultTaskTimer */
	BaseType_t xHigherPriorityTaskWoken = pdFALSE;
	if (defaultTaskHandle != NULL)
	{
		xTaskNotifyFromISR(defaultTaskHandle,
			DEFAULTTSKBIT00,	/* 'or' bit assigned to buffer to notification value. */
			eSetBits,      /* Set 'or' option */
			&xHigherPriorityTaskWoken );
	}

  /* USER CODE END CallbackdefaultTaskTimer */
}

void HAL_TIM_PeriodElapsedCallback(TIM_HandleTypeDef *htim)
{
  if (htim->Instance == TIM12) {
    HAL_IncTick();
  }
}

void Error_Handler(void)
{
  /* USER CODE BEGIN Error_Handler_Debug */
  /* User can add his own implementation to report the HAL error return state */
	morse_trap(m_trap); // Flash error code set in earlier MX Init()'s

  /* USER CODE END Error_Handler_Debug */
}

#ifdef  USE_FULL_ASSERT
/**
  * @brief  Reports the name of the source file and the source line number
  *         where the assert_param error has occurred.
  * @param  file: pointer to the source file name
  * @param  line: assert_param error line source number
  * @retval None
  */
void assert_failed(uint8_t *file, uint32_t line)
{
  /* USER CODE BEGIN 6 */
  /* User can add his own implementation to report the file name and line number,
     tex: printf("Wrong parameters value: file %s on line %d\r\n", file, line) */
morse_trap(222);
  /* USER CODE END 6 */
}
#endif /* USE_FULL_ASSERT */

/************************ (C) COPYRIGHT STMicroelectronics *****END OF FILE****/
